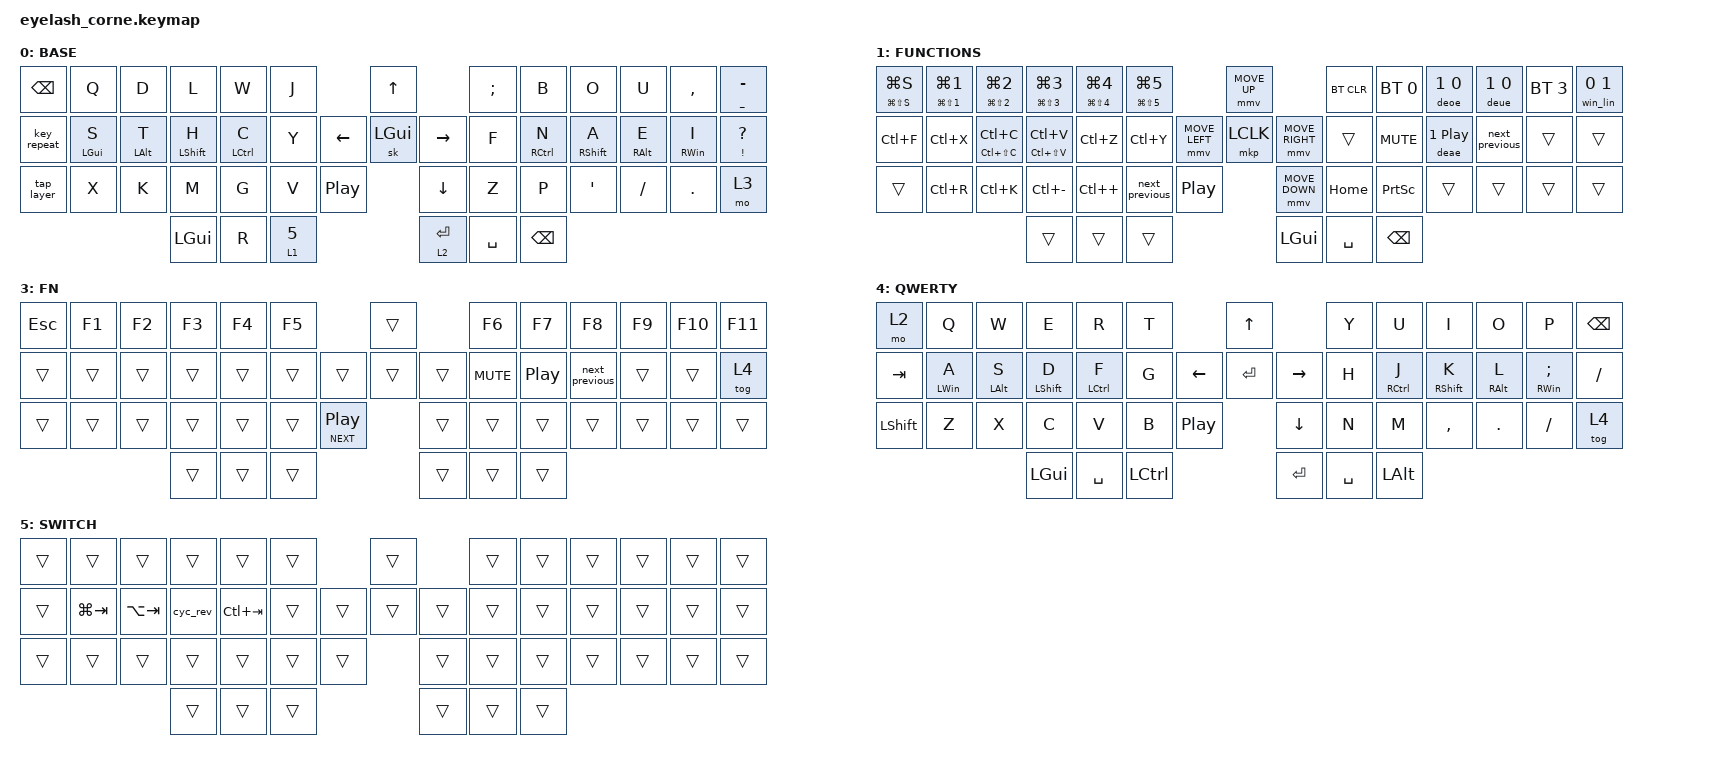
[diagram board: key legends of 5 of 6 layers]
#include <behaviors.dtsi>
#include <behaviors/unicode.dtsi> // for zmk-unicode

/* ----- For default ZMK behavior ---- */
#include <dt-bindings/zmk/bt.h>
#include <dt-bindings/zmk/keys.h>

#include <dt-bindings/zmk/mouse.h>
#include <dt-bindings/zmk/pointing.h>
#include <dt-bindings/zmk/outputs.h>
#include <dt-bindings/zmk/rgb.h>
#include <dt-bindings/zmk/behaviors.h>

/* ----- Extra zmk modules ---- */
#include <zmk-unicode/keys-extra.h>
#include "zmk-helpers/helper.h"
#include <input/processors.dtsi>
#include "german.dtsi"

/* Mouse input processing default values*/
#undef ZMK_MOUSE_DEFAULT_MOVE_VAL
#undef ZMK_MOUSE_DEFAULT_SCRL_VAL
#define ZMK_MOUSE_DEFAULT_MOVE_VAL 1000  // 600
#define ZMK_MOUSE_DEFAULT_SCRL_VAL 20   // 10

#define ZMK_POINTING_DEFAULT_MOVE_VAL 800  // default: 600
#define ZMK_POINTING_DEFAULT_SCRL_VAL 100    // default: 10

&mmv {
  acceleration-exponent = <1>;      // 1
  time-to-max-speed-ms = <500>;     // 300
  delay-ms = <0>;                   // 0
};

&msc {
  acceleration-exponent = <1>;      // 0
  time-to-max-speed-ms = <150>;     // 300
  delay-ms = <0>;                   // 0
};

 &uc {
  default-mode = <UC_MODE_WIN_COMPOSE>;
  minimum-length = <0>;
};

/ {
    behaviors {
        // ---- Cyclotab (module in this repo, src/cyclotab.c) ----
        // tap the Tab thumb key = arm SWITCH layer; tap it twice = plain Tab
        cyc_layer: cyc_layer {
            compatible = "zmk,behavior-cyclotab-layer";
            #binding-cells = <1>;
            arm-timeout-ms = <1500>;
        };

        // during a switch: go back one window (no Shift holding needed)
        cyc_rev: cyc_rev {
            compatible = "zmk,behavior-cyclotab-reverse";
            #binding-cells = <0>;
        };

        // &sw_lt 1 5: hold = layer 1 (as before), tap = start the SWITCH layer 5
        sw_lt: sw_lt {
            compatible = "zmk,behavior-hold-tap";
            #binding-cells = <2>;
            flavor = "tap-preferred";
            tapping-term-ms = <200>;
            bindings = <&mo>, <&cyc_layer>;
        };

        // SYMBOLS encoder: turn = Alt+Tab (Cyclotab), stop turning = select.
        // Press the encoder (&cyc_mode) to switch to Ctrl+Tab (browser tabs).
        Tab_switching: Tab_switching {
            compatible = "zmk,behavior-cyclotab-encoder";
            #sensor-binding-cells = <0>;
            keys = <LA(TAB) LS(LA(TAB)) LC(TAB) LS(LC(TAB))>;
            timeout-ms = <600>;   // select this long after the last detent
        };

        // umlaut mode indicator for the right screen (0 = Windows, 1 = Linux), runs on both halves
        uc_ind: uc_ind {
            compatible = "zmk,behavior-uc-indicator";
            #binding-cells = <1>;
        };

        cyc_mode: cyc_mode {
            compatible = "zmk,behavior-cyclotab-mode";
            #binding-cells = <0>;
        };

        tap_layer: tap_layer {
            compatible = "zmk,behavior-tap-dance";
            label = "TAP_LAYER";
            #binding-cells = <0>;
            bindings = <&mo 2>, <&kp CAPSLOCK>;
        };

        next_previous: next_previous {
            compatible = "zmk,behavior-tap-dance";
            label = "NEXT_PREVIOUS";
            #binding-cells = <0>;
            bindings = <&kp C_NEXT>, <&kp C_PREVIOUS>;
        };

        // BASE encoder: smooth scrolling (module src/smooth_scroll.c)
        scroll_encoder: scroll_encoder {
            compatible = "zmk,behavior-smooth-scroll";
            #sensor-binding-cells = <0>;
            notch-percent = <65>;               // scroll per detent: 65% of a mouse-wheel notch
            smooth-ms = <16>;                   // short glide per detent (0 = one report per detent like a real wheel)
            tick-ms = <4>;                      // 4 small reports per detent
            acceleration-window-ms = <120>;     // only fast spinning accelerates
            max-acceleration-percent = <250>;   // up to 2.5x at full speed
        };

    };

    combos { compatible = "zmk,combos";

        esc_q_combo: esc_q_combo {
            timeout-ms = <50>;
            key-positions = <0 1>; // positions of the keys in the matrix here
            bindings = <&kp ESC>;  // what combo sends
            layers = <0 4 5>;   // 5 = SWITCH, so Esc can cancel a switch
        };

        enter_combo: enter_combo {
            timeout-ms = <50>;
            key-positions = <14 15>; // positions of the keys in the matrix
            bindings = <&kp ENTER>;  // what combo sends

        };

        backspace: backspace {
            timeout-ms = <50>;
            key-positions = <15 16>; // positions of the keys in the matrix
            bindings = <&kp BACKSPACE>;  // what combo sends

        };

        space: space {
            timeout-ms = <50>;
            key-positions = <17 16>; // positions of the keys in the matrix
            bindings = <&kp SPACE>;  // what combo sends
            layers = <0>;

        };

        skip_previous: skip_previous {
            timeout-ms = <50>;
            key-positions = <17 16>; // positions of the keys in the matrix
            bindings = <&next_previous>;  // what combo sends
            layers = <1>;

        };

        // FUNCTIONS layer: Mute + ä key together = sticky Shift (then hold ä -> Ä)
        sticky_shift_fn: sticky_shift_fn {
            timeout-ms = <50>;
            key-positions = <23 24>;
            bindings = <&sk LSHIFT>;
            layers = <1>;
        };

        back {
            bindings = <&kp BACKSPACE>;
            key-positions = <2 3>;
            layers = <0>;
            timeout-ms = <50>;
        };

        del {
            bindings = <&kp DELETE>;
            key-positions = <3 4>;
            layers = <0>;
            timeout-ms = <50>;
        };

        hash {
            bindings = <&kp HASH>;
            key-positions = <16 3>;
            layers = <0>;
            timeout-ms = <50>;
        };

        at {
            bindings = <&kp AT_SIGN>;
            key-positions = <15 2>;
            layers = <0>;
            timeout-ms = <50>;
        };

    };

    macros {
        bt2: bt2 {
            compatible = "zmk,behavior-macro";
            #binding-cells = <0>;
            bindings = <&bt BT_SEL 2>;
            label = "BT2";
        };
        bt1: bt1 {
            compatible = "zmk,behavior-macro";
            #binding-cells = <0>;
            bindings = <&bt BT_SEL 1>;
            label = "BT1";
        };
        ae: ae {
            compatible = "zmk,behavior-macro";
            #binding-cells = <0>;
            bindings = <&uc UC_DE_AE>;
            label = "ae";
        };
        ue: ue {
            compatible = "zmk,behavior-macro";
            #binding-cells = <0>;
            bindings = <&uc UC_DE_UE>;
            label = "ue";
        };
        oe: oe {
            compatible = "zmk,behavior-macro";
            #binding-cells = <0>;
            bindings = <&uc UC_DE_OE>;
            label = "uoee";
        };
        win: win {
            compatible = "zmk,behavior-macro";
            #binding-cells = <0>;
            bindings = <&uc UC_SET_WIN_COMPOSE>, <&uc_ind 0>;
            label = "win";
        };
        lin: lin {
            compatible = "zmk,behavior-macro";
            #binding-cells = <0>;
            bindings = <&uc UC_SET_LINUX>, <&uc_ind 1>;
            label = "lin";
        };

    };

    /*
     * Key position numbers (for key-positions in combos):
     *
     *   row 1:  0   1   2   3   4   5             6         7   8   9  10  11  12
     *   row 2: 13  14  15  16  17  18        19  20  21    22  23  24  25  26  27
     *   row 3: 28  29  30  31  32  33  34        35        36  37  38  39  40  41
     *   thumb:             42  43  44                45    46  47
     */

    // Cyclotab: these hotkeys keep their modifier held after release, anywhere in the keymap
    cyclotab: cyclotab {
        compatible = "zmk,cyclotab";
        keys = <LA(TAB) LS(LA(TAB)) LG(TAB) LS(LG(TAB)) LC(TAB) LS(LC(TAB))>;
        timeout-ms = <1000>;   // 0 = no timeout
    };

    keymap {
        compatible = "zmk,keymap";

        default_layer {
            display-name = "BASE";
            bindings = <
                &kp BACKSPACE  &kp Q        &kp D            &kp L              &kp W         &kp J                                     &kp UP_ARROW                  &kp SEMI   &kp B          &kp O               &kp U             &kp COMMA         &hmr UNDER MINUS
                &key_repeat    &hmr LGUI S  &hmr LEFT_ALT T  &hmr LEFT_SHIFT H  &hmr LCTRL C  &kp Y                           &kp LEFT  &sk LGUI      &kp RIGHT       &kp F      &hmr RCTRL N   &hmr RIGHT_SHIFT A  &hmr RIGHT_ALT E  &hmr RIGHT_WIN I  &hmr EXCL QUESTION
                &tap_layer     &kp X        &kp K            &kp M              &kp G         &kp V      &kp C_PLAY_PAUSE               &kp DOWN                      &kp Z      &kp P          &kp APOS            &kp FSLH          &kp DOT           &mo 3
                                                             &kp LGUI           &kp R         &sw_lt 1 5                                              &lt 2 ENTER     &kp SPACE  &kp BACKSPACE
            >;

            sensor-bindings = <&scroll_encoder>;
        };

        lower_layer {
            display-name = "FUNCTIONS";
            bindings = <
                &hmr LG(LS(S)) LG(S)  &hmr LG(LS(N1)) LG(NUMBER_1)  &hmr LG(LS(N2)) LG(NUMBER_2)  &hmr LG(LS(N3)) LG(NUMBER_3)  &hmr LG(LS(N4)) LG(NUMBER_4)  &hmr LG(LS(N5)) LG(NUMBER_5)                                       &mmv MOVE_UP                        &bt BT_CLR  &bt BT_SEL 0   &deoe 1 0             &deue 1 0       &bt BT_SEL 3  &win_lin 0 1
                &kp LC(F)             &kp LC(X)                     &hmr LC(LS(C)) LC(C)          &hmr LC(LS(V)) LC(V)          &kp LC(Z)                     &kp LC(Y)                                          &mmv MOVE_LEFT  &mkp LCLK       &mmv MOVE_RIGHT     &trans      &kp K_MUTE     &deae 1 C_PLAY_PAUSE  &next_previous  &trans        &trans
                &trans                &kp LC(R)                     &kp LC(K)                     &kp LC(MINUS)                 &kp LC(PLUS)                  &next_previous                &kp C_PLAY_PAUSE                     &mmv MOVE_DOWN                      &kp HOME    &kp PSCRN      &trans                &trans          &trans        &trans
                                                                                                  &trans                        &trans                        &trans                                                                             &kp LGUI            &kp SPACE   &kp BACKSPACE
            >;

            sensor-bindings = <&inc_dec_kp C_VOLUME_UP C_VOL_DN>;
        };

        raise_layer {
            display-name = "SYMBOLS";
            bindings = <
                &kp GRAVE  &kp NUMBER_1     &kp NUMBER_2                    &kp NUMBER_3                       &kp NUMBER_4     &kp N5                                        &msc SCRL_UP                        &kp NUMBER_6        &kp N7            &kp N8                     &kp N9                  &kp N0     &kp BSPC
                &kp MINUS  &hmr LGUI EQUAL  &hmr LEFT_ALT LEFT_PARENTHESIS  &hmr LEFT_SHIFT RIGHT_PARENTHESIS  &hmr LCTRL BSLH  &kp APOS                      &msc SCRL_LEFT  &kp LG(F)       &msc SCRL_RIGHT     &hmr HOME LC(LEFT)  &kp LEFT_ARROW    &scrl MOVE_Y(40) UP_ARROW  &scrl MOVE_Y(-40) DOWN  &kp RIGHT  &hmr END LC(RIGHT)
                &kp COMMA  &kp DOT          &kp LBKT                        &kp RBKT                           &kp FSLH         &sk LEFT_ALT  &cyc_mode                       &msc SCRL_DOWN                      &kp HOME            &hmr PSCRN LG(P)  &trans                     &trans                  &kp END    &kp ENTER
                                                                            &sk LCTRL                          &sk LEFT_SHIFT   &sk LGUI                                                      &trans              &trans              &trans
            >;

            sensor-bindings = <&Tab_switching>;
        };

        Fn_layer {
            display-name = "FN";
            bindings = <
                &kp ESC  &kp F1  &kp F2  &kp F3  &kp F4  &kp F5                                       &trans             &kp F6      &kp F7            &kp F8          &kp F9  &kp F10  &kp F11
                &trans   &trans  &trans  &trans  &trans  &trans                               &trans  &trans  &trans     &kp C_MUTE  &kp C_PLAY_PAUSE  &next_previous  &trans  &trans   &tog 4
                &trans   &trans  &trans  &trans  &trans  &trans  &hmr C_NEXT C_PLAY_PAUSE             &trans             &trans      &trans            &trans          &trans  &trans   &trans
                                         &trans  &trans  &trans                                               &trans     &trans      &trans
            >;

            sensor-bindings = <&inc_dec_kp C_VOLUME_UP C_VOL_DN>;
        };

        QWERTY {
            display-name = "QWERTY";
            bindings = <
                &mo 2      &kp Q            &kp W            &kp E              &kp R         &kp T                                           &kp UP_ARROW                        &kp Y      &kp U         &kp I               &kp O             &kp P                     &kp BSPC
                &kp TAB    &hmr LEFT_WIN A  &hmr LEFT_ALT S  &hmr LEFT_SHIFT D  &hmr LCTRL F  &kp G                           &kp LEFT_ARROW  &kp ENTER       &kp RIGHT_ARROW     &kp H      &hmr RCTRL J  &hmr RIGHT_SHIFT K  &hmr RIGHT_ALT L  &hmr RIGHT_WIN SEMICOLON  &kp FSLH
                &kp LSHFT  &kp Z            &kp X            &kp C              &kp V         &kp B      &kp C_PLAY_PAUSE                     &kp DOWN_ARROW                      &kp N      &kp M         &kp COMMA           &kp DOT           &kp FSLH                  &tog 4
                                                             &kp LGUI           &kp SPACE     &kp LCTRL                                                       &kp ENTER           &kp SPACE  &kp LALT
            >;

            sensor-bindings = <&inc_dec_kp C_VOLUME_UP C_VOL_DN>;
        };

        SWITCH {
            display-name = "SWITCH";
            bindings = <
                &trans        &trans        &trans        &trans        &trans        &trans        &trans        &trans        &trans        &trans        &trans        &trans        &trans
                &trans        &kp LG(TAB)   &kp LA(TAB)   &cyc_rev      &kp LC(TAB)   &trans        &trans        &trans        &trans        &trans        &trans        &trans        &trans        &trans        &trans
                &trans        &trans        &trans        &trans        &trans        &trans        &trans        &trans        &trans        &trans        &trans        &trans        &trans        &trans
                &trans        &trans        &trans        &trans        &trans        &trans
            >;
        };

    };
};
